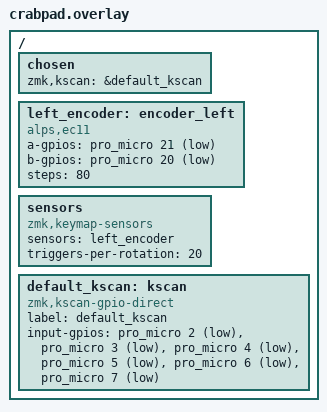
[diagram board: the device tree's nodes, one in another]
/ {
    chosen {
        zmk,kscan = &default_kscan;
    };

    left_encoder: encoder_left {
        compatible = "alps,ec11";
        a-gpios = <&pro_micro 21 (GPIO_ACTIVE_LOW | GPIO_PULL_UP)>;
        b-gpios = <&pro_micro 20 (GPIO_ACTIVE_LOW | GPIO_PULL_UP)>;
        steps = <80>;
        status = "okay";
    };

    sensors: sensors {
        compatible = "zmk,keymap-sensors";
        sensors = <&left_encoder>;
        triggers-per-rotation = <20>;
    };

    default_kscan: kscan {
        compatible = "zmk,kscan-gpio-direct";
        label = "default_kscan";

        input-gpios =
            <&pro_micro 2 (GPIO_ACTIVE_LOW | GPIO_PULL_UP)>,
            <&pro_micro 3 (GPIO_ACTIVE_LOW | GPIO_PULL_UP)>,
            <&pro_micro 4 (GPIO_ACTIVE_LOW | GPIO_PULL_UP)>,
            <&pro_micro 5 (GPIO_ACTIVE_LOW | GPIO_PULL_UP)>,
            <&pro_micro 6 (GPIO_ACTIVE_LOW | GPIO_PULL_UP)>,
            <&pro_micro 7 (GPIO_ACTIVE_LOW | GPIO_PULL_UP)>;
    };
};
